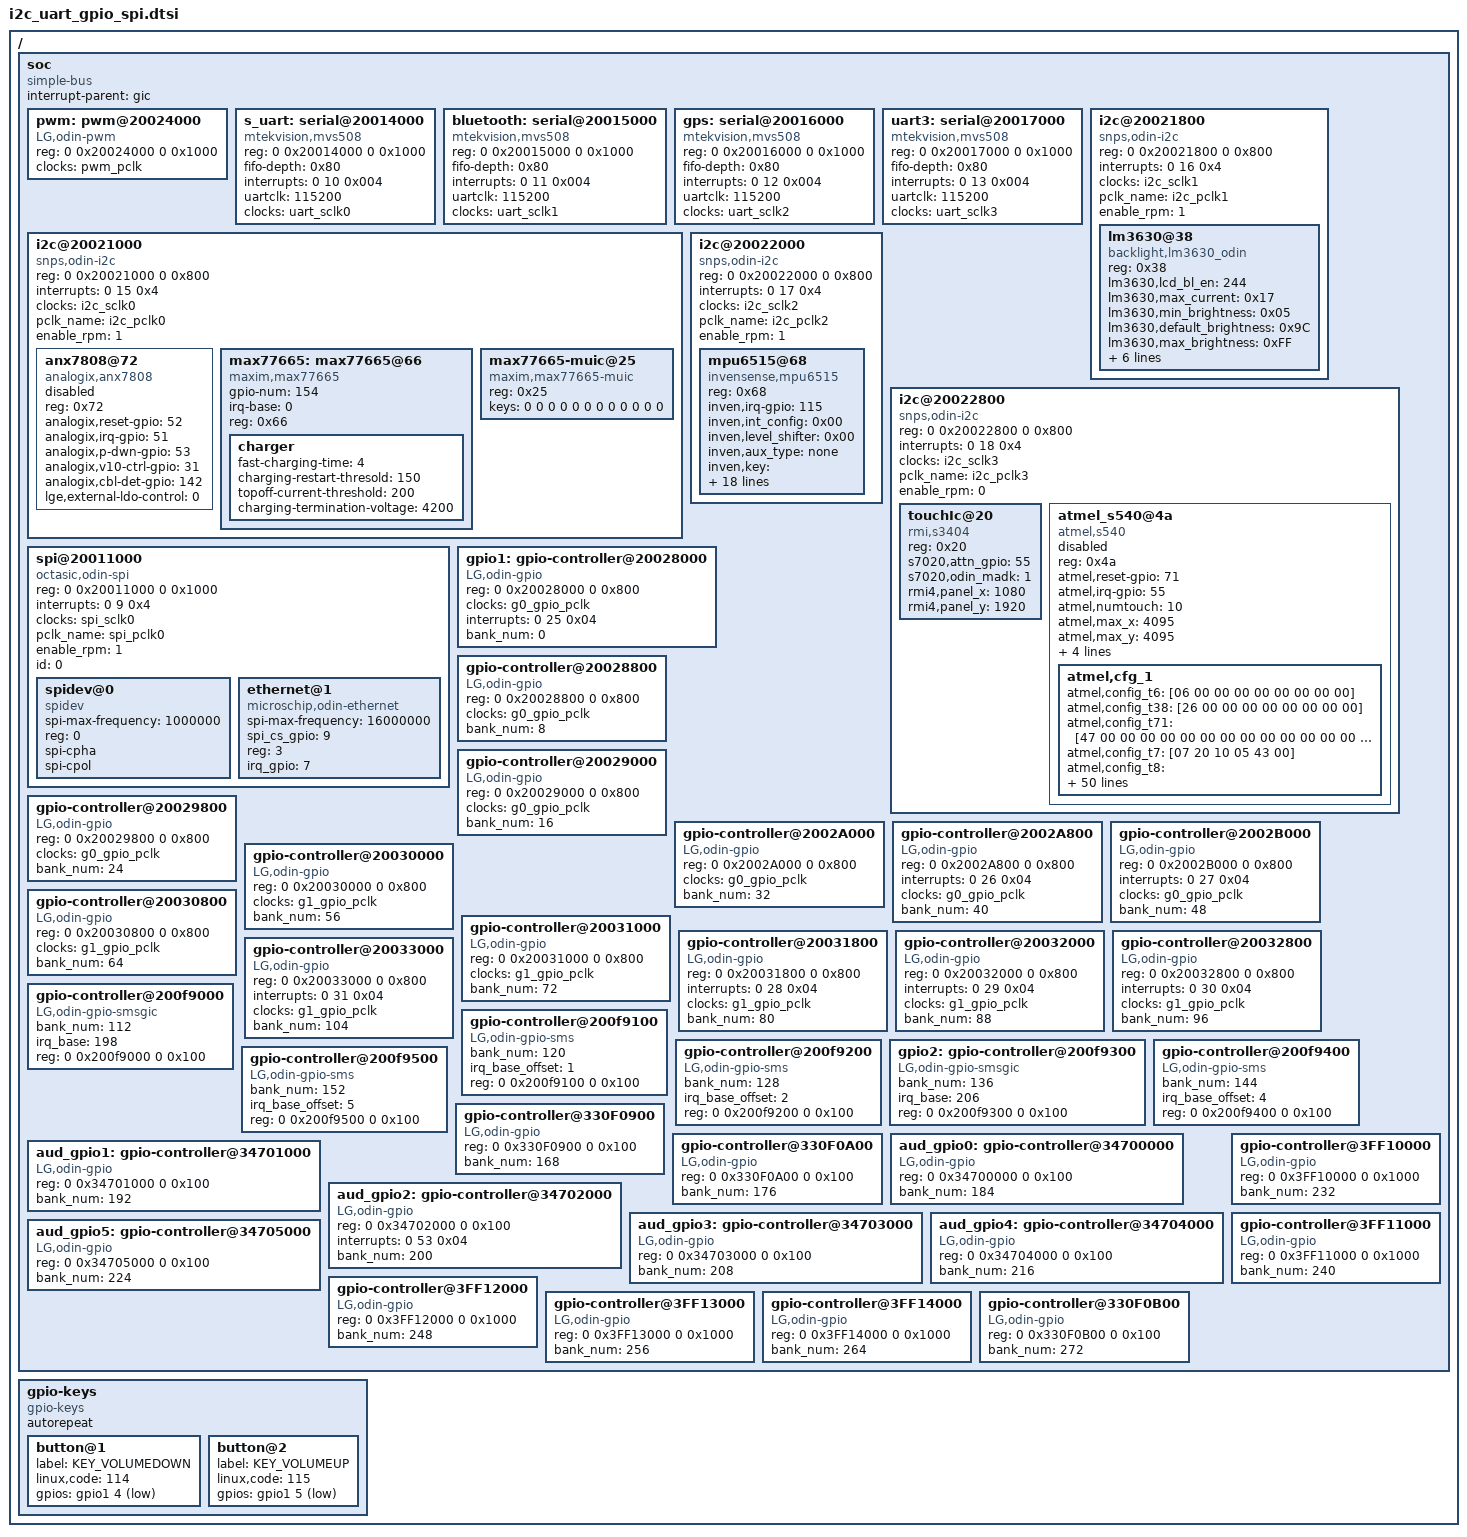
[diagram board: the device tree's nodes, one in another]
/*
 * LG Electronics I2C for ODIN/Woden
 */

/ {
	soc{
		compatible = "simple-bus";
  		interrupt-parent = <&gic>;
		#address-cells = <2>;
		#size-cells = <2>;
		ranges;

		pwm: pwm@20024000 {
			compatible = "LG,odin-pwm";
			reg = <0 0x20024000 0 0x1000>;
			clocks = <&pwm_pclk>;
			#pwm-cells = <3>;
		};

		s_uart: serial@20014000 {
			compatible = "mtekvision,mvs508";
			reg = <0 0x20014000 0 0x1000>;
			fifo-depth = <0x80>;
			interrupts = <0 10 0x004>;
			uartclk = <115200>;
			clocks = <&uart_sclk0>;
		};

		bluetooth: serial@20015000 {
			compatible = "mtekvision,mvs508";
			reg = <0 0x20015000 0 0x1000>;
			fifo-depth = <0x80>;
			interrupts = <0 11 0x004>;
			uartclk = <115200>;
			clocks = <&uart_sclk1>;
		};

		gps: serial@20016000 {
			compatible = "mtekvision,mvs508";
			reg = <0 0x20016000 0 0x1000>;
			fifo-depth = <0x80>;
			interrupts = <0 12 0x004>;
			uartclk = <115200>;
			clocks = <&uart_sclk2>;
		};

		uart3: serial@20017000 {
			compatible = "mtekvision,mvs508";
			reg = <0 0x20017000 0 0x1000>;
			fifo-depth = <0x80>;
			interrupts = <0 13 0x004>;
			uartclk = <115200>;
			clocks = <&uart_sclk3>;
		};


/* i2c start */

		i2c@20021000 {
			compatible = "snps,odin-i2c";
			reg = <0 0x20021000 0 0x800>;
			interrupts = <0 15 0x4>;
			clocks = <&i2c_sclk0>;
			pclk_name = "i2c_pclk0";
			enable_rpm = <1>;
			#address-cells = <1>;
			#size-cells = <0>;

			/* LGE_CHANGE_S
			 */
			anx7808@72{
				compatible = "analogix,anx7808";
				status = "disabled";
				reg = <0x72>;
				analogix,reset-gpio = <52>; /* PERI_G0_GPIO_BASE(0)+52 */
				analogix,irq-gpio = <51>;   /* PERI_G0_GPIO_BASE(0)+51 */
				analogix,p-dwn-gpio = <53>; /* PERI_G0_GPIO_BASE(0)+53 */
				analogix,v10-ctrl-gpio = <31>;  /* PERI_G0_GPIO_BASE(0)+31 */
				analogix,cbl-det-gpio = <142>;  /* SMS_GPIO_BASE(112)+30 */
				lge,external-ldo-control = <0>;
			};

			max77665: max77665@66{
				compatible = "maxim,max77665";
				/* sms-gpio base (112) + sms-gpio #42 = 154 */
				gpio-num = <154>;
				irq-base = <0>;
				reg = <0x66>;

				charger {
					fast-charging-time = <4>;
					charging-restart-thresold = <150>;
					topoff-current-threshold = <200>;
					charging-termination-voltage = <4200>;
				};
			};

            max77665-muic@25{
				compatible = "maxim,max77665-muic";
				reg = <0x25>;
				keys = <0 0 0 0 0 0 0 0 0 0 0 0>;
			};
		};

		i2c@20021800 {
			compatible = "snps,odin-i2c";
			reg = <0 0x20021800 0 0x800>;
			interrupts = <0 16 0x4>;
			clocks = <&i2c_sclk1>;
			pclk_name = "i2c_pclk1";
			enable_rpm = <1>;
			#address-cells = <1>;
			#size-cells = <0>;

			lm3630@38{
				compatible = "backlight,lm3630_odin";
				status = "ok";
				reg = <0x38>;
				lm3630,lcd_bl_en = <244>;	/* ICS GPIO 12 default for madk 1v1 */
				lm3630,max_current = <0x17>;
				lm3630,min_brightness = <0x05>;
				lm3630,default_brightness = <0x9C>;
				lm3630,max_brightness = <0xFF>;
				lm3630,enable_pwm = <1>;
				lm3630,blmap_size = <256>;
				lm3630,blmap = <
					3 3 3 3 3 3 3 3 4 4 4 4 4 4 4
					4 4 4 4 4 4 4 5 5 5 5 5 5 5 5
					5 5 5 5 5 6 6 6 6 6 6 6 6 7 7
					7 8 8 8 9 9 9 9 9 10 10 10 11 11 11
					12 12 12 12 13 13 13 13 14 14 15 15 15 16 16
					17 17 17 18 18 18 19 19 20 21 22 22 23 24 24
					25 25 26 26 27 28 28 29 29 30 30 31 31 32 32
					33 34 35 35 36 36 37 38 39 39 40 41 41 42 43
					44 45 45 46 47 48 49 50 51 52 53 54 55 56 57
					58 59 60 61 62 63 64 65 66 67 68 69 70 71 72
					73 74 75 76 76 77 78 80 81 82 83 85 86 87 88
					89 90 91 93 95 96 97 99 100 102 103 104 106 107 108
					109 110 112 114 115 117 119 121 123 125 127 128 129 130 132
					133 135 136 138 139 140 142 144 146 148 150 151 153 154 156
					157 158 159 161 163 164 165 167 168 170 173 175 177 180 184
					186 188 191 194 197 199 201 203 205 207 209 211 213 215 217
					219 221 223 225 227 228 230 232 235 238 240 243 246 249 252
					255>;
				pwms = <&pwm 0 1024 1>;
				pwm-names = "lm3630-pwm";
				};
		};

		i2c@20022000 {
			compatible = "snps,odin-i2c";
			reg = <0 0x20022000 0 0x800>;
			interrupts = <0 17 0x4>;
			clocks = <&i2c_sclk2>;
			pclk_name = "i2c_pclk2";
			enable_rpm = <1>;
/* LGE_CHANGE_S
*/
			mpu6515@68{
				compatible = "invensense,mpu6515";
				reg = <0x68>;
				inven,irq-gpio = <115>;		/*	SMS_GPIO_BASE(112) + 3	*/
				inven,int_config = <0x00>;
				inven,level_shifter = <0x00>;
				/* inven,secondary_type = "none"; */
				inven,aux_type = "none";
				inven,key = [4e cc 7e eb f6 1e 35 22 00 34 0d 65 32 e9 94 89];
				axis_map_x = <0>;
				axis_map_y = <1>;
				axis_map_z = <2>;
				negate_x = <0>;
				negate_y = <0>;
				negate_z = <0>;

				poll_interval = <200>;
				min_interval = <5>;
				inven,secondary_reg = <0x0D>;
				/* If no compass sensor,
				* replace "compass" with "none"
				*/
				inven,secondary_type = "none";
				inven,secondary_name = "ak8963";
				inven,secondary_axis_map_x = <1>;
				inven,secondary_axis_map_y = <0>;
				inven,secondary_axis_map_z = <2>;
				inven,secondary_negate_x = <0>;
				inven,secondary_negate_y = <0>;
				inven,secondary_negate_z = <1>;
			};
/* LGE_CHANGE_E */
		};

		i2c@20022800 {
			compatible = "snps,odin-i2c";
			reg = <0 0x20022800 0 0x800>;
			interrupts = <0 18 0x4>;
			clocks = <&i2c_sclk3>;
			pclk_name = "i2c_pclk3";
			enable_rpm = <0>;
			#address-cells = <1>;
			#size-cells = <0>;

			    touchIc@20  {
                	compatible = "rmi,s3404","TouchIC,s7020_odin" ;
					status = "ok";
	                reg = <0x20>;
                    s7020,attn_gpio = <55>;
                    s7020,odin_madk = <1>;
                    rmi4,panel_x = <1080>;
                    rmi4,panel_y = <1920>;
                };

				atmel_s540@4a {
					compatible = "atmel,s540";
					status = "disabled";
					reg = <0x4a>;
					atmel,reset-gpio = <71>;
					atmel,irq-gpio = <55>;
					atmel,numtouch = <10>;
					atmel,max_x = <4095>;
					atmel,max_y = <4095>;
					atmel,irqflags = <0x00000002>;
					atmel,t19_num_keys = <0>;
					atmel,accuracy_filter_enable = <0>;
					atmel,ghost_detection_enable = <0>;
					/* config : B1_mxt540S_Character_ver_config_1104.xcfg */
					atmel,cfg_1 {
						atmel,config_t6 = [06
							00 00 00 00 00 00 00 /*dummy*/00];
						atmel,config_t38 = [26
							00 00 00 00 00 00 00 00];
						atmel,config_t71 = [47
							00 00 00 00 00 00 00 00 00 00
							00 00 00 00 00 00 00 00 00 00
							00 00 00 00 00 00 00 00 00 00
							00 00 00 00 00 00 00 00 00 00
							00 00 00 00 00 00 00 00 00 00
							00 00 00 00 00 00 00 00 00 00
							00 00 00 00 00 00 00 00 00 00
							00 00 00 00 00 00 00 00 00 00
							00 00 00 00 00 00 00 00 00 00
							00 00 00 00 00 00 00 00 00 00
							00 00 00 00 00 00 00 00 00 00
							00 00];
						atmel,config_t7 = [07
							20 10 05 43 00];
						atmel,config_t8 = [08
							50 00 05 01 00 00 FF 01 00 00
							00 00 00 00 00 /*dummy*/00];
						atmel,config_t15 = [0F
							00 00 00 04 02 00 00 1E 00 00
							00 /*dummy*/00];
						atmel,config_t18 = [12
							00 00];
						atmel,config_t19 = [13
							00 00 00 00 00 00];
						atmel,config_t23 = [17
							00 00 00 00 00 00 00 00 00 00
							00 00 00 00 00 00];
						atmel,config_t24 = [18
							03 01 08 00 08 32 00 00 00 00
							00 00 00 00 00 C8 00 00 00 /*dummy*/00];
						atmel,config_t25 = [19
							03 00 30 75 F0 55 30 75 F0 55
							30 75 F0 55 C8 A0 0F A0 0F A0
							0F];
						atmel,config_t35 = [23
							03 08 08 02 03 05 19 00 08 00
							03 02 04 01 02 04 01 05 42 09
							00 04 05 02 04 01 02 04 01 05
							42 09 00 04 03 02 04 01 02 04
							01 05 42 06 00 01 04 02 05 02
							05 47 05 00 03 04 05 02 05 41
							05 00 03 04 05 01 05 41 05 04
							03 04 03 04 05 4D 05 03 04 03
							04 03 05 57 06 00 01 04 02 04
							01 05 53 06 00 01 04 02 03 01
							05 47 04 00 01 04 02 05 43 06
							00 03 04 01 02 01 05 2A 03 03
							04 02 03 55 00 00 00 00];
						atmel,config_t40 = [28
							00 00 00 00 00];
						atmel,config_t42 = [2A
							00 00 00 00 00 00 00 00 00 00 00
							00 00];
						atmel,config_t46 = [2E
							04 00 08 10 00 00 04 00 00 01];
						atmel,config_t47 = [2F
							09 11 28 FF 02 19 0A A0 01 20
							E0 E0 03 00 00 00 00 00 00 00
							01 00 90 16 AA 3C];
						atmel,config_t55 = [37
							00 00 00 00 00 00 00 /*dummy*/00];
						atmel,config_t56 = [38
							01 00 01 6E 03 03 03 03 03 03
							03 05 05 05 05 05 05 05 05 05
							05 05 05 05 05 05 05 05 05 05
							05 06 05 00 00 00];
						atmel,config_t61 = [3D
							00 00 00 00 00	/*instance 0*/
							00 00 00 00 00];	/*instance 1*/
						atmel,config_t65 = [41
							01 01 00 00 00 00 00 00 00 00
							00 00 00 00 00 00 00 00 00 00];
						atmel,config_t66 = [42
							00 00 00 /*dummy*/00 00];
						atmel,config_t69 = [45
							00 00 00 00 00 00 00 00 00];
						atmel,config_t70 = [46
							00 00 00 00 00 00 00 00 00 00	/*instance 0*/
							00 00 00 00 00 00 00 00 00 00	/*instance 1*/
							00 00 00 00 00 00 00 00 00 00	/*instance 2*/
							00 00 00 00 00 00 00 00 00 00	/*instance 3*/
							00 00 00 00 00 00 00 00 00 00	/*instance 4*/
							00 00 00 00 00 00 00 00 00 00	/*instance 5*/
							00 00 00 00 00 00 00 00 00 00	/*instance 6*/
							00 00 00 00 00 00 00 00 00 00];	/*instance 7*/
						atmel,config_t72 = [48
							01 00 00 11 00 14 0A 05 02 30
							14 19 04 03 20 28 0D 50 00 00
							00 01 02 05 07 0C 10 10 10 10
							10 08 08 08 08 08 00 00 08 00
							09 01 02 05 06 07 2A 2A 2A 2A
							2A 20 20 20 20 20 00 07 10 00
							09 2D 33 42 48 52 34 34 34 34
							34 20 20 20 20 20 00 0F 00 34];
						atmel,config_t78 = [4E
							00 00 00 00 00 00 00 00 00];
						atmel,config_t80 = [50
							00 00 00 00 00 00 00 /*dummy*/00];
						atmel,config_t84 = [54
							00 00 00 00];
						atmel,config_t100 = [64
							83 3C 07 02 00 00 0A 88 00 1E
							2D 02 02 FF 0E 16 1B 00 00 00
							11 2D 05 05 6F 08 23 2D 07 03
							3C 0A 19 00 00 19 00 0F 00 02
							01 01 00 23 02 DC 30 0A 00 04
							00 00 00 04];
						atmel,config_t101 = [65
							00 00 00 00 00 00 00 00 00 00
							00 00 00 00 00 00 00 00 00 00
							00 00 00 00 00];
						atmel,config_t102 = [66
							00 00 00 00 00 00 00 00 00 00
							00 00 00 00 00 00 00 00 00 00
							00 00 00 00 00 00 00 00 00 00];
						atmel,config_t103 = [67
							00 00 00 00 00 00 00 00 00 00
							00 00 00 00 /*instance 0*/
							00 00 00 00 00 00 00 00 00 00
							00 00 00 00 /*instance 1*/];
						atmel,config_t104 = [68
							00 00 00 00 00 00 00 00 00 00
							00 /*dummy*/00];
						atmel,config_t105 = [69
							00 00 00 00 00 00 00 00 00 00
							00 00 00 00 00 00 00 00];
					};
			};
		};
/* i2c end */

/* spi start */
		spi@20011000 {
			compatible = "octasic,odin-spi";
			reg = <0 0x20011000 0 0x1000>;
			interrupts = <0 9 0x4>;
			clocks = <&spi_sclk0>;
			pclk_name = "spi_pclk0";
			enable_rpm = <1>;
			id = <0>;
			#address-cells = <1>;
			#size-cells = <0>;

			spidev@0{
				compatible = "spidev";
				spi-max-frequency = <1000000>;
				reg = <0>;
				spi-cpha;
				spi-cpol;
			};

			ethernet@1{
				compatible = "microschip,odin-ethernet";
				spi-max-frequency = <16000000>;
				spi_cs_gpio = <9>;
				reg = <3>;
				irq_gpio = <7>;
			};
		};

/* spi end */
/*---- peri gpio controller ----*/
/* G0_GPIO0~6 */
		gpio1: gpio-controller@20028000 {
			#gpio-cells = <2>;
			compatible = "LG,odin-gpio";
			reg = <0 0x20028000 0 0x800>;
			clocks = <&g0_gpio_pclk>;
			interrupts = <0 25 0x04>;
			bank_num = <0>;
		};
		gpio-controller@20028800 {
			compatible = "LG,odin-gpio";
			reg = <0 0x20028800 0 0x800>;
			clocks = <&g0_gpio_pclk>;
			bank_num = <8>;
		};
		gpio-controller@20029000 {
			compatible = "LG,odin-gpio";
			reg = <0 0x20029000 0 0x800>;
			clocks = <&g0_gpio_pclk>;
			bank_num = <16>;
		};
		gpio-controller@20029800 {
			compatible = "LG,odin-gpio";
			reg = <0 0x20029800 0 0x800>;
			clocks = <&g0_gpio_pclk>;
			bank_num = <24>;
		};
		gpio-controller@2002A000 {
			compatible = "LG,odin-gpio";
			reg = <0 0x2002A000 0 0x800>;
			clocks = <&g0_gpio_pclk>;
			bank_num = <32>;
		};
		gpio-controller@2002A800 {
			compatible = "LG,odin-gpio";
			reg = <0 0x2002A800 0 0x800>;
			interrupts = <0 26 0x04>;
			clocks = <&g0_gpio_pclk>;
			bank_num = <40>;
		};
		gpio-controller@2002B000 {
			compatible = "LG,odin-gpio";
			reg = <0 0x2002B000 0 0x800>;
			interrupts = <0 27 0x04>;
			clocks = <&g0_gpio_pclk>;
			bank_num = <48>;
		};
	/* G1_GPIO0~6 */
		gpio-controller@20030000 {
			compatible = "LG,odin-gpio";
			reg = <0 0x20030000 0 0x800>;
			clocks = <&g1_gpio_pclk>;
			bank_num = <56>;
		};
		gpio-controller@20030800 {
			compatible = "LG,odin-gpio";
			reg = <0 0x20030800 0 0x800>;
			clocks = <&g1_gpio_pclk>;
			bank_num = <64>;
		};
		gpio-controller@20031000 {
			compatible = "LG,odin-gpio";
			reg = <0 0x20031000 0 0x800>;
			clocks = <&g1_gpio_pclk>;
			bank_num = <72>;
		};
		gpio-controller@20031800 {
			compatible = "LG,odin-gpio";
			reg = <0 0x20031800 0 0x800>;
			interrupts = <0 28 0x04>;
			clocks = <&g1_gpio_pclk>;
			bank_num = <80>;
		};
		gpio-controller@20032000 {
			compatible = "LG,odin-gpio";
			reg = <0 0x20032000 0 0x800>;
			interrupts = <0 29 0x04>;
			clocks = <&g1_gpio_pclk>;
			bank_num = <88>;
		};
		gpio-controller@20032800 {
			compatible = "LG,odin-gpio";
			reg = <0 0x20032800 0 0x800>;
			interrupts = <0 30 0x04>;
			clocks = <&g1_gpio_pclk>;
			bank_num = <96>;
		};
		gpio-controller@20033000 {
			compatible = "LG,odin-gpio";
			reg = <0 0x20033000 0 0x800>;
			interrupts = <0 31 0x04>;
			clocks = <&g1_gpio_pclk>;
			bank_num = <104>;
		};
	/*---- peri gpio controller end ----*/

	/*---- sms gpio controller ----*/
		gpio-controller@200f9000 {
			compatible = "LG,odin-gpio-smsgic";
			bank_num = <112>;
			irq_base = <198>;
			reg = <0 0x200f9000 0 0x100>;
		};
		gpio-controller@200f9100 {
			compatible = "LG,odin-gpio-sms";
			bank_num = <120>;
			irq_base_offset = <1>;
			reg = <0 0x200f9100 0 0x100>;
		};
		gpio-controller@200f9200 {
			compatible = "LG,odin-gpio-sms";
			bank_num = <128>;
			irq_base_offset = <2>;
			reg = <0 0x200f9200 0 0x100>;
		};
		gpio2:gpio-controller@200f9300 {
			#gpio-cells = <2>;
			compatible = "LG,odin-gpio-smsgic";
			bank_num = <136>;
			irq_base = <206>;
			reg = <0 0x200f9300 0 0x100>;
		};
		gpio-controller@200f9400 {
			compatible = "LG,odin-gpio-sms";
			bank_num = <144>;
			irq_base_offset = <4>;
			reg = <0 0x200f9400 0 0x100>;
		};
		gpio-controller@200f9500 {
			compatible = "LG,odin-gpio-sms";
			bank_num = <152>;
			irq_base_offset = <5>;
			reg = <0 0x200f9500 0 0x100>;
		};
	/*---- sms gpio controller end ----*/
	/*---- css gpio controller ----*/
		gpio-controller@330F0900 {
			compatible = "LG,odin-gpio";
			reg = <0 0x330F0900 0 0x100>;
			bank_num = <168>;
		};
		gpio-controller@330F0A00 {
			compatible = "LG,odin-gpio";
			reg = <0 0x330F0A00 0 0x100>;
			bank_num = <176>;
		};
	/*---- css gpio controller end ----*/
	/*---- aud gpio controller ----*/
		aud_gpio0: gpio-controller@34700000{
			compatible = "LG,odin-gpio";
			reg = <0 0x34700000 0 0x100>;
			bank_num = <184>;
		};
		aud_gpio1: gpio-controller@34701000{
			compatible = "LG,odin-gpio";
			reg = <0 0x34701000 0 0x100>;
			bank_num = <192>;
		};
		aud_gpio2: gpio-controller@34702000{
			compatible = "LG,odin-gpio";
			reg = <0 0x34702000 0 0x100>;
			interrupts = <0 53 0x04>;
			bank_num = <200>;
		};
		aud_gpio3: gpio-controller@34703000{
			compatible = "LG,odin-gpio";
			reg = <0 0x34703000 0 0x100>;
			bank_num = <208>;
		};
		aud_gpio4: gpio-controller@34704000{
			compatible = "LG,odin-gpio";
			reg = <0 0x34704000 0 0x100>;
			bank_num = <216>;
		};
		aud_gpio5: gpio-controller@34705000{
			compatible = "LG,odin-gpio";
			reg = <0 0x34705000 0 0x100>;
			bank_num = <224>;
		};
	/*---- aud gpio controller end ----*/
	/*---- ics gpio controller start ----*/
		gpio-controller@3FF10000 {
			compatible = "LG,odin-gpio";
			reg = <0 0x3FF10000 0 0x1000>;
			bank_num = <232>;
		};
		gpio-controller@3FF11000 {
			compatible = "LG,odin-gpio";
			reg = <0 0x3FF11000 0 0x1000>;
			bank_num = <240>;
		};
		gpio-controller@3FF12000 {
			compatible = "LG,odin-gpio";
			reg = <0 0x3FF12000 0 0x1000>;
			bank_num = <248>;
		};
		gpio-controller@3FF13000 {
			compatible = "LG,odin-gpio";
			reg = <0 0x3FF13000 0 0x1000>;
			bank_num = <256>;
		};
		gpio-controller@3FF14000 {
			compatible = "LG,odin-gpio";
			reg = <0 0x3FF14000 0 0x1000>;
			bank_num = <264>;
		};
	/*---- ics gpio controller end ----*/
	/*---- css gpio controller ----*/
		gpio-controller@330F0B00 {
			compatible = "LG,odin-gpio";
			reg = <0 0x330F0B00 0 0x100>;
			bank_num = <272>;
		};
	/*---- css gpio controller end ----*/

	};

	gpio-keys {
		compatible = "gpio-keys";
		#address-cells = <1>;
		#size-cells = <0>;
		autorepeat;
		button@1 {
			label = "KEY_VOLUMEDOWN";
			linux,code = <114>;
			gpios = <&gpio1 4 1>;
		};
		button@2 {
			label = "KEY_VOLUMEUP";
			linux,code = <115>;
			gpios = <&gpio1 5 1>;
		};
	};
};
